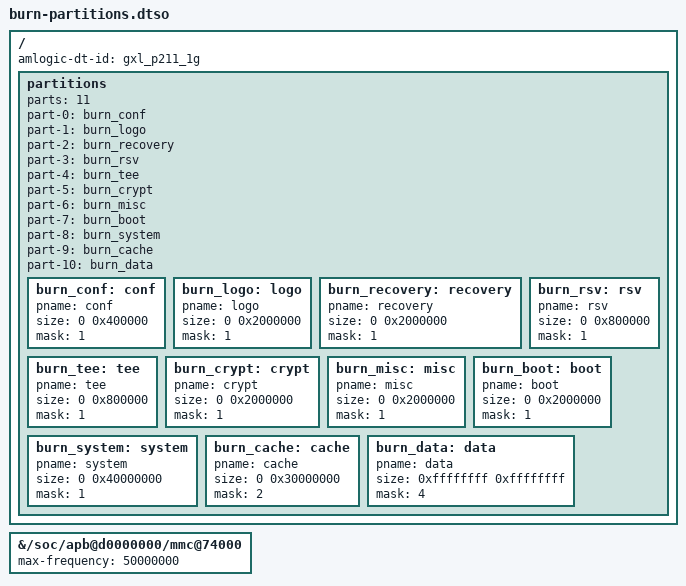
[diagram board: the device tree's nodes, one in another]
/dts-v1/;
/plugin/;

/ {
	fragment@0 {
		target-path = "/";

		__overlay__ {
			amlogic-dt-id = "gxl_p211_1g";

			partitions {
				parts = <11>;
				part-0 = <&burn_conf>;
				part-1 = <&burn_logo>;
				part-2 = <&burn_recovery>;
				part-3 = <&burn_rsv>;
				part-4 = <&burn_tee>;
				part-5 = <&burn_crypt>;
				part-6 = <&burn_misc>;
				part-7 = <&burn_boot>;
				part-8 = <&burn_system>;
				part-9 = <&burn_cache>;
				part-10 = <&burn_data>;

				burn_conf: conf {
					pname = "conf";
					size = <0 0x400000>;
					mask = <1>;
				};

				burn_logo: logo {
					pname = "logo";
					size = <0 0x2000000>;
					mask = <1>;
				};

				burn_recovery: recovery {
					pname = "recovery";
					size = <0 0x2000000>;
					mask = <1>;
				};

				burn_rsv: rsv {
					pname = "rsv";
					size = <0 0x800000>;
					mask = <1>;
				};

				burn_tee: tee {
					pname = "tee";
					size = <0 0x800000>;
					mask = <1>;
				};

				burn_crypt: crypt {
					pname = "crypt";
					size = <0 0x2000000>;
					mask = <1>;
				};

				burn_misc: misc {
					pname = "misc";
					size = <0 0x2000000>;
					mask = <1>;
				};

				burn_boot: boot {
					pname = "boot";
					size = <0 0x2000000>;
					mask = <1>;
				};

				burn_system: system {
					pname = "system";
					size = <0 0x40000000>;
					mask = <1>;
				};

				burn_cache: cache {
					pname = "cache";
					size = <0 0x30000000>;
					mask = <2>;
				};

				burn_data: data {
					pname = "data";
					size = <0xffffffff 0xffffffff>;
					mask = <4>;
				};
			};
		};
	};

	fragment@1 {
		target-path = "/soc/apb@d0000000/mmc@74000";

		__overlay__ {
			max-frequency = <50000000>;
		};
	};
};
